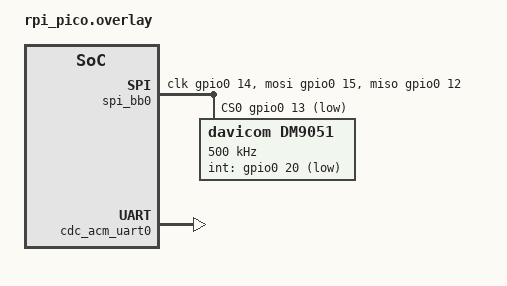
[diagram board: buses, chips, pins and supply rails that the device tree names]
#include <zephyr/dt-bindings/gpio/gpio.h>

/* SPI bitbang GPIO: MISO=12, CS=13, SCK=14, MOSI=15
 * DM9051 INT=20 (active low)
 */

/ {
    chosen {
        zephyr,console = &cdc_acm_uart0;
        zephyr,shell-uart = &cdc_acm_uart0;
    };
};

&zephyr_udc0 {
    cdc_acm_uart0: cdc_acm_uart0 {
        compatible = "zephyr,cdc-acm-uart";
    };
};

/ {
    spi_bb0: spi_bitbang0 {
        compatible = "zephyr,spi-bitbang";
        status = "okay";
        #address-cells = <1>;
        #size-cells = <0>;

        clk-gpios = <&gpio0 14 GPIO_ACTIVE_HIGH>;
        mosi-gpios = <&gpio0 15 GPIO_ACTIVE_HIGH>;
        miso-gpios = <&gpio0 12 GPIO_ACTIVE_HIGH>;
        cs-gpios = <&gpio0 13 GPIO_ACTIVE_LOW>;

        dm9051: ethernet@0 {
            compatible = "davicom,dm9051";
            reg = <0>;
            spi-max-frequency = <500000>;
            int-gpios = <&gpio0 20 GPIO_ACTIVE_LOW>;
            status = "okay";
        };
    };
};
